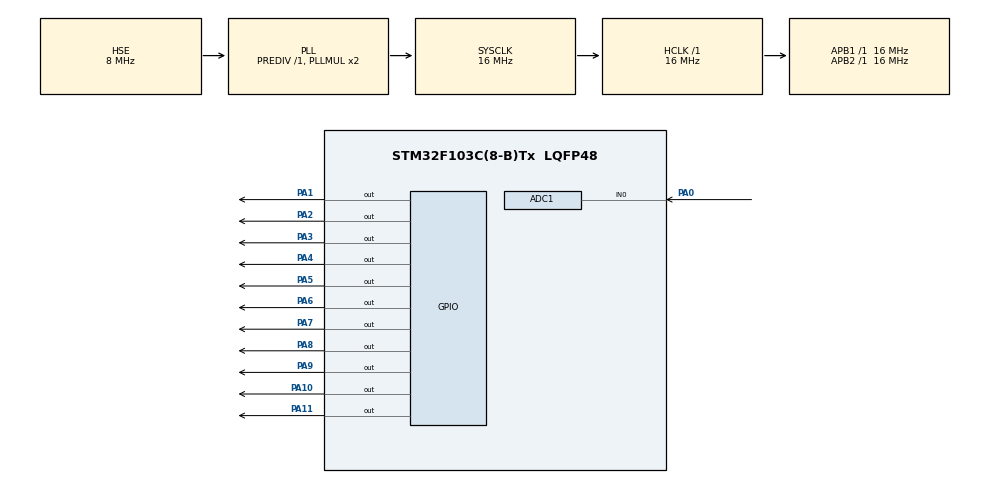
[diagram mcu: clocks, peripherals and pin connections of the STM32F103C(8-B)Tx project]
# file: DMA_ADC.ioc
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ADC1.Channel-0\#ChannelRegularConversion=ADC_CHANNEL_0
ADC1.ContinuousConvMode=ENABLE
ADC1.NbrOfConversionFlag=1
ADC1.Rank-0\#ChannelRegularConversion=1
ADC1.SamplingTime-0\#ChannelRegularConversion=ADC_SAMPLETIME_41CYCLES_5
ADC1.master=1
Dma.ADC1.0.Direction=DMA_PERIPH_TO_MEMORY
Dma.ADC1.0.Instance=DMA1_Channel1
Dma.ADC1.0.MemDataAlignment=DMA_MDATAALIGN_WORD
Dma.ADC1.0.MemInc=DMA_MINC_ENABLE
Dma.ADC1.0.Mode=DMA_CIRCULAR
Dma.ADC1.0.PeriphDataAlignment=DMA_PDATAALIGN_WORD
Dma.ADC1.0.PeriphInc=DMA_PINC_DISABLE
Dma.ADC1.0.Priority=DMA_PRIORITY_LOW
Dma.Request0=ADC1
Mcu.Family=STM32F1
Mcu.Name=STM32F103C(8-B)Tx
Mcu.Package=LQFP48
NVIC.DMA1_Channel1_IRQn=true\:0\:0\:false\:false\:true\:false\:true\:true
NVIC.PriorityGroup=NVIC_PRIORITYGROUP_4
PA0-WKUP.Signal=ADCx_IN0
PA1.Signal=GPIO_Output
PA10.Signal=GPIO_Output
PA11.Signal=GPIO_Output
PA13.Mode=Serial_Wire
PA13.Signal=SYS_JTMS-SWDIO
PA14.Mode=Serial_Wire
PA14.Signal=SYS_JTCK-SWCLK
PA2.Signal=GPIO_Output
PA3.Signal=GPIO_Output
PA4.Signal=GPIO_Output
PA5.Signal=GPIO_Output
PA6.Signal=GPIO_Output
PA7.Signal=GPIO_Output
PA8.Signal=GPIO_Output
PA9.Signal=GPIO_Output
PD0-OSC_IN.Mode=HSE-External-Oscillator
PD0-OSC_IN.Signal=RCC_OSC_IN
PD1-OSC_OUT.Mode=HSE-External-Oscillator
PD1-OSC_OUT.Signal=RCC_OSC_OUT
ProjectManager.HeapSize=0x200
ProjectManager.StackSize=0x400
ProjectManager.TargetToolchain=MDK-ARM V5.32
RCC.AHBFreq_Value=16000000
RCC.APB1Freq_Value=16000000
RCC.APB1TimFreq_Value=16000000
RCC.APB2Freq_Value=16000000
RCC.APB2TimFreq_Value=16000000
RCC.HCLKFreq_Value=16000000
RCC.PLLSourceVirtual=RCC_PLLSOURCE_HSE
RCC.SYSCLKFreq_VALUE=16000000
RCC.SYSCLKSource=RCC_SYSCLKSOURCE_PLLCLK
RCC.USBFreq_Value=16000000
SH.ADCx_IN0.0=ADC1_IN0,IN0
board=custom

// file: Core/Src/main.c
/* USER CODE BEGIN Header */
/**
  ******************************************************************************
  * @file           : main.c
  * @brief          : Main program body
  ******************************************************************************
  * @attention
  *
  * Copyright (c) 2025 STMicroelectronics.
  * All rights reserved.
  *
  * This software is licensed under terms that can be found in the LICENSE file
  * in the root directory of this software component.
  * If no LICENSE file comes with this software, it is provided AS-IS.
  *
  ******************************************************************************
  */
/* USER CODE END Header */
#include "main.h"
#include "adc.h"
#include "dma.h"
#include "gpio.h"
#include "lcd.h"
#include "stdio.h"

void SystemClock_Config(void);

int adc_val[300];
char str[16];
int n_data = 300;
float vi,av;
void HAL_ADC_ConvCpltCallback(ADC_HandleTypeDef* hadc)
{
	uint32_t s = 0;
	for(int i =0; i < n_data; i++)
	{
		s+=adc_val[i];
	}
	av = (float)s/(n_data*1.00);

}
int main(void)
{

  /* MCU Configuration--------------------------------------------------------*/

  /* Reset of all peripherals, Initializes the Flash interface and the Systick. */
  HAL_Init();

  /* Configure the system clock */
  SystemClock_Config();

  /* Initialize all configured peripherals */
  MX_GPIO_Init();
  MX_DMA_Init();
  MX_ADC1_Init();

  /* Infinite loop */
  /* USER CODE BEGIN WHILE */
	lcd_init();
	lcd_puts("lcd_init");
	HAL_ADC_Start_DMA(&hadc1,adc_val,n_data);
  while (1)
  {
    /* USER CODE END WHILE */

    /* USER CODE BEGIN 3 */

		sprintf(str,"vi = %0.3f",av/4095*3.3/2);
		lcd_clear();
		lcd_puts(str);
  }
  /* USER CODE END 3 */
}

void SystemClock_Config(void)
{
  RCC_OscInitTypeDef RCC_OscInitStruct = {0};
  RCC_ClkInitTypeDef RCC_ClkInitStruct = {0};
  RCC_PeriphCLKInitTypeDef PeriphClkInit = {0};

  /** Initializes the RCC Oscillators according to the specified parameters
  * in the RCC_OscInitTypeDef structure.
  */
  RCC_OscInitStruct.OscillatorType = RCC_OSCILLATORTYPE_HSE;
  RCC_OscInitStruct.HSEState = RCC_HSE_ON;
  RCC_OscInitStruct.HSEPredivValue = RCC_HSE_PREDIV_DIV1;
  RCC_OscInitStruct.HSIState = RCC_HSI_ON;
  RCC_OscInitStruct.PLL.PLLState = RCC_PLL_ON;
  RCC_OscInitStruct.PLL.PLLSource = RCC_PLLSOURCE_HSE;
  RCC_OscInitStruct.PLL.PLLMUL = RCC_PLL_MUL2;
  if (HAL_RCC_OscConfig(&RCC_OscInitStruct) != HAL_OK)
  {
    Error_Handler();
  }

  /** Initializes the CPU, AHB and APB buses clocks
  */
  RCC_ClkInitStruct.ClockType = RCC_CLOCKTYPE_HCLK|RCC_CLOCKTYPE_SYSCLK
                              |RCC_CLOCKTYPE_PCLK1|RCC_CLOCKTYPE_PCLK2;
  RCC_ClkInitStruct.SYSCLKSource = RCC_SYSCLKSOURCE_PLLCLK;
  RCC_ClkInitStruct.AHBCLKDivider = RCC_SYSCLK_DIV1;
  RCC_ClkInitStruct.APB1CLKDivider = RCC_HCLK_DIV1;
  RCC_ClkInitStruct.APB2CLKDivider = RCC_HCLK_DIV1;

  if (HAL_RCC_ClockConfig(&RCC_ClkInitStruct, FLASH_LATENCY_0) != HAL_OK)
  {
    Error_Handler();
  }
  PeriphClkInit.PeriphClockSelection = RCC_PERIPHCLK_ADC;
  PeriphClkInit.AdcClockSelection = RCC_ADCPCLK2_DIV2;
  if (HAL_RCCEx_PeriphCLKConfig(&PeriphClkInit) != HAL_OK)
  {
    Error_Handler();
  }
}

void Error_Handler(void)
{
  __disable_irq();
  while (1)
  {
  }
}
